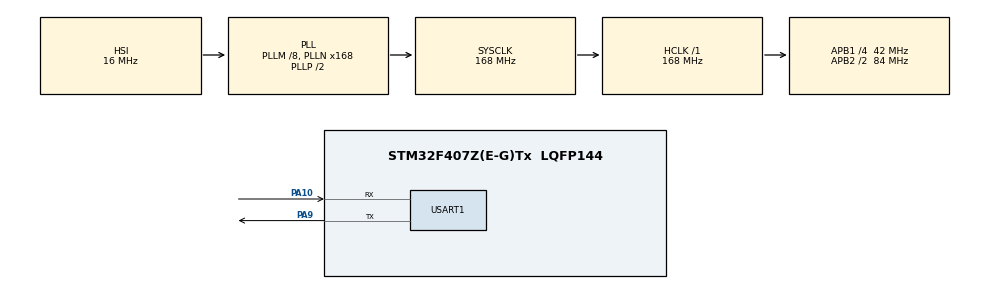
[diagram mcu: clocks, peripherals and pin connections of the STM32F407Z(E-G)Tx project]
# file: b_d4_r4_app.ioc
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Mcu.Family=STM32F4
Mcu.Name=STM32F407Z(E-G)Tx
Mcu.Package=LQFP144
NVIC.PriorityGroup=NVIC_PRIORITYGROUP_4
NVIC.TIM1_UP_TIM10_IRQn=true\:15\:0\:false\:false\:true\:false\:true\:true
NVIC.TimeBase=TIM1_UP_TIM10_IRQn
NVIC.TimeBaseIP=TIM1
PA10.Mode=Asynchronous
PA10.Signal=USART1_RX
PA13.Mode=Serial_Wire
PA13.Signal=SYS_JTMS-SWDIO
PA14.Mode=Serial_Wire
PA14.Signal=SYS_JTCK-SWCLK
PA9.Mode=Asynchronous
PA9.Signal=USART1_TX
PC14-OSC32_IN.Mode=LSE-External-Oscillator
PC14-OSC32_IN.Signal=RCC_OSC32_IN
PC15-OSC32_OUT.Mode=LSE-External-Oscillator
PC15-OSC32_OUT.Signal=RCC_OSC32_OUT
PH0-OSC_IN.Mode=HSE-External-Oscillator
PH0-OSC_IN.Signal=RCC_OSC_IN
PH1-OSC_OUT.Mode=HSE-External-Oscillator
PH1-OSC_OUT.Signal=RCC_OSC_OUT
ProjectManager.HeapSize=0x800
ProjectManager.StackSize=0x800
ProjectManager.TargetToolchain=STM32CubeIDE
RCC.48MHZClocksFreq_Value=84000000
RCC.AHBFreq_Value=168000000
RCC.APB1CLKDivider=RCC_HCLK_DIV4
RCC.APB1Freq_Value=42000000
RCC.APB1TimFreq_Value=84000000
RCC.APB2CLKDivider=RCC_HCLK_DIV2
RCC.APB2Freq_Value=84000000
RCC.APB2TimFreq_Value=168000000
RCC.CortexFreq_Value=168000000
RCC.HCLKFreq_Value=168000000
RCC.HSE_VALUE=25000000
RCC.HSI_VALUE=16000000
RCC.PLLM=8
RCC.PLLN=168
RCC.SYSCLKFreq_VALUE=168000000
RCC.SYSCLKSource=RCC_SYSCLKSOURCE_PLLCLK
RCC.VCOOutputFreq_Value=336000000
STMicroelectronics.X-CUBE-AI.10.2.0.ActivationBufferSizeList=102132
STMicroelectronics.X-CUBE-AI.10.2.0.ActivationBuffers=pool0
STMicroelectronics.X-CUBE-AI.10.2.0.ActivationNames=pool0
STMicroelectronics.X-CUBE-AI.10.2.0.ActivationSizes=AI_B_D4_R4_DATA_ACTIVATION_1_SIZE
STMicroelectronics.X-CUBE-AI.10.2.0.ApplicationCcDeviceJjApplication=ApplicationTemplate
STMicroelectronics.X-CUBE-AI.10.2.0.HeapSize=0x800
STMicroelectronics.X-CUBE-AI.10.2.0.InternalRamActivationBufferMaxSize=AI_B_D4_R4_DATA_ACTIVATIONS_SIZE
STMicroelectronics.X-CUBE-AI.10.2.0.LatestDirectoryUsed-ca483bc52d37d4bbcf959bbb9a56b1262452131387698af6a58597110d267cb7=G\:\\dd_tmp\\cubeai_validate_b_d4_r4
STMicroelectronics.X-CUBE-AI.10.2.0.MaximumNumberOfInputLayer=1
STMicroelectronics.X-CUBE-AI.10.2.0.MaximumNumberOfOutputLayer=1
STMicroelectronics.X-CUBE-AI.10.2.0.MaximumSizeOfInputLayer=1
STMicroelectronics.X-CUBE-AI.10.2.0.MaximumSizeOfOutputLayer=1
STMicroelectronics.X-CUBE-AI.10.2.0.ModelActualCompression-ca483bc52d37d4bbcf959bbb9a56b1262452131387698af6a58597110d267cb7=0.0
STMicroelectronics.X-CUBE-AI.10.2.0.ModelCompression-ca483bc52d37d4bbcf959bbb9a56b1262452131387698af6a58597110d267cb7=None
STMicroelectronics.X-CUBE-AI.10.2.0.ModelFlashOccupation-ca483bc52d37d4bbcf959bbb9a56b1262452131387698af6a58597110d267cb7=21992
STMicroelectronics.X-CUBE-AI.10.2.0.ModelHashList=ca483bc52d37d4bbcf959bbb9a56b1262452131387698af6a58597110d267cb7
STMicroelectronics.X-CUBE-AI.10.2.0.ModelKind-ca483bc52d37d4bbcf959bbb9a56b1262452131387698af6a58597110d267cb7=TFLITE
STMicroelectronics.X-CUBE-AI.10.2.0.ModelMacc-ca483bc52d37d4bbcf959bbb9a56b1262452131387698af6a58597110d267cb7=14712726
STMicroelectronics.X-CUBE-AI.10.2.0.ModelName-ca483bc52d37d4bbcf959bbb9a56b1262452131387698af6a58597110d267cb7=b_d4_r4
STMicroelectronics.X-CUBE-AI.10.2.0.ModelNameList=b_d4_r4
STMicroelectronics.X-CUBE-AI.10.2.0.ModelRamOccupation-ca483bc52d37d4bbcf959bbb9a56b1262452131387698af6a58597110d267cb7=102132
STMicroelectronics.X-CUBE-AI.10.2.0.ModelStructureFile-ca483bc52d37d4bbcf959bbb9a56b1262452131387698af6a58597110d267cb7=/G\:/dd_tmp/b_d4_r4_int8_logits.tflite
STMicroelectronics.X-CUBE-AI.10.2.0.ModelType-ca483bc52d37d4bbcf959bbb9a56b1262452131387698af6a58597110d267cb7=STM32Cube.AI MCU runtime
STMicroelectronics.X-CUBE-AI.10.2.0.ReadyForCodeGeneration=true
STMicroelectronics.X-CUBE-AI.10.2.0.StackSize=0x800
STMicroelectronics.X-CUBE-AI.10.2.0.ValidationInputFile-ca483bc52d37d4bbcf959bbb9a56b1262452131387698af6a58597110d267cb7=G\:\\dd_tmp\\cubeai_validate_b_d4_r4\\val_input_int8_logits.npy
STMicroelectronics.X-CUBE-AI.10.2.0.ValidationInputFileHistory-ca483bc52d37d4bbcf959bbb9a56b1262452131387698af6a58597110d267cb7=G\:\\dd_tmp\\cubeai_validate_b_d4_r4\\val_input_int8_logits.npy
STMicroelectronics.X-CUBE-AI.10.2.0.ValidationOutputFile-ca483bc52d37d4bbcf959bbb9a56b1262452131387698af6a58597110d267cb7=G\:\\dd_tmp\\cubeai_validate_b_d4_r4\\val_output_int8_logits.npy
STMicroelectronics.X-CUBE-AI.10.2.0.ValidationOutputFileHistory-ca483bc52d37d4bbcf959bbb9a56b1262452131387698af6a58597110d267cb7=G\:\\dd_tmp\\cubeai_validate_b_d4_r4\\val_output_int8_logits.npy
STMicroelectronics.X-CUBE-AI.10.2.0.WorkingBufferStartAddrList=0xFFFFFFFF
STMicroelectronics.X-CUBE-AI.10.2.0.XAaCUBEAaAICcArtificialOoIntelligenceJjCore=true
STMicroelectronics.X-CUBE-AI.10.2.0.copyWeightToRam-ca483bc52d37d4bbcf959bbb9a56b1262452131387698af6a58597110d267cb7=false
STMicroelectronics.X-CUBE-AI.10.2.0.customLayerConfigEnabled-ca483bc52d37d4bbcf959bbb9a56b1262452131387698af6a58597110d267cb7=false
STMicroelectronics.X-CUBE-AI.10.2.0.noOnnxIoTranspose-ca483bc52d37d4bbcf959bbb9a56b1262452131387698af6a58597110d267cb7=false
STMicroelectronics.X-CUBE-AI.10.2.0.outputDirectory-ca483bc52d37d4bbcf959bbb9a56b1262452131387698af6a58597110d267cb7=E\:\\ST_Repository\\.stm32cubemx
STMicroelectronics.X-CUBE-AI.10.2.0.useInputAllocation-ca483bc52d37d4bbcf959bbb9a56b1262452131387698af6a58597110d267cb7=true
STMicroelectronics.X-CUBE-AI.10.2.0.useOutputAllocation-ca483bc52d37d4bbcf959bbb9a56b1262452131387698af6a58597110d267cb7=true
USART1.VirtualMode=VM_ASYNC
VP_STMicroelectronics.X-CUBE-AI_VS_ArtificialOoIntelligenceJjXAaCUBEAaAI_10.2.0.Mode=ArtificialOoIntelligenceJjXAaCUBEAaAI
VP_STMicroelectronics.X-CUBE-AI_VS_DeviceJjApplication_10.2.0.Mode=DeviceJjApplication
VP_SYS_VS_tim1.Mode=TIM1
board=custom

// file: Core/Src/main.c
/* USER CODE BEGIN Header */
/**
  ******************************************************************************
  * @file           : main.c
  * @brief          : Main program body
  ******************************************************************************
  * @attention
  *
  * Copyright (c) 2026 STMicroelectronics.
  * All rights reserved.
  *
  * This software is licensed under terms that can be found in the LICENSE file
  * in the root directory of this software component.
  * If no LICENSE file comes with this software, it is provided AS-IS.
  *
  ******************************************************************************
  */
/* USER CODE END Header */
#include "main.h"
#include "usart.h"
#include "gpio.h"
#include "app_x-cube-ai.h"

void SystemClock_Config(void);

int main(void)
{

  /* MCU Configuration--------------------------------------------------------*/

  /* Reset of all peripherals, Initializes the Flash interface and the Systick. */
  HAL_Init();

  /* Configure the system clock */
  SystemClock_Config();

  /* Initialize all configured peripherals */
  MX_GPIO_Init();
  MX_USART1_UART_Init();
  MX_X_CUBE_AI_Init();
  /* USER CODE BEGIN 2 */
  uint8_t ai_process_done = 0U;

  /* USER CODE END 2 */

  /* Infinite loop */
  while (1)
  {

    if (ai_process_done == 0U)
    {
      ai_process_done = 1U;
      MX_X_CUBE_AI_Process();
    }
  }
}

void SystemClock_Config(void)
{
  RCC_OscInitTypeDef RCC_OscInitStruct = {0};
  RCC_ClkInitTypeDef RCC_ClkInitStruct = {0};

  /** Configure the main internal regulator output voltage
  */
  __HAL_RCC_PWR_CLK_ENABLE();
  __HAL_PWR_VOLTAGESCALING_CONFIG(PWR_REGULATOR_VOLTAGE_SCALE1);

  /** Initializes the RCC Oscillators according to the specified parameters
  * in the RCC_OscInitTypeDef structure.
  */
  RCC_OscInitStruct.OscillatorType = RCC_OSCILLATORTYPE_HSI;
  RCC_OscInitStruct.HSIState = RCC_HSI_ON;
  RCC_OscInitStruct.HSICalibrationValue = RCC_HSICALIBRATION_DEFAULT;
  RCC_OscInitStruct.PLL.PLLState = RCC_PLL_ON;
  RCC_OscInitStruct.PLL.PLLSource = RCC_PLLSOURCE_HSI;
  RCC_OscInitStruct.PLL.PLLM = 8;
  RCC_OscInitStruct.PLL.PLLN = 168;
  RCC_OscInitStruct.PLL.PLLP = RCC_PLLP_DIV2;
  RCC_OscInitStruct.PLL.PLLQ = 4;
  if (HAL_RCC_OscConfig(&RCC_OscInitStruct) != HAL_OK)
  {
    Error_Handler();
  }

  /** Initializes the CPU, AHB and APB buses clocks
  */
  RCC_ClkInitStruct.ClockType = RCC_CLOCKTYPE_HCLK|RCC_CLOCKTYPE_SYSCLK
                              |RCC_CLOCKTYPE_PCLK1|RCC_CLOCKTYPE_PCLK2;
  RCC_ClkInitStruct.SYSCLKSource = RCC_SYSCLKSOURCE_PLLCLK;
  RCC_ClkInitStruct.AHBCLKDivider = RCC_SYSCLK_DIV1;
  RCC_ClkInitStruct.APB1CLKDivider = RCC_HCLK_DIV4;
  RCC_ClkInitStruct.APB2CLKDivider = RCC_HCLK_DIV2;

  if (HAL_RCC_ClockConfig(&RCC_ClkInitStruct, FLASH_LATENCY_5) != HAL_OK)
  {
    Error_Handler();
  }
}

/* USER CODE BEGIN 4 */
int __io_putchar(int ch)
{
  uint8_t c = (uint8_t)ch;

  (void)HAL_UART_Transmit(&huart1, &c, 1U, HAL_MAX_DELAY);

  return ch;
}

/* USER CODE END 4 */

void HAL_TIM_PeriodElapsedCallback(TIM_HandleTypeDef *htim)
{
  if (htim->Instance == TIM1) {
    HAL_IncTick();
  }
}

void Error_Handler(void)
{
  __disable_irq();
  while (1)
  {
  }
}
